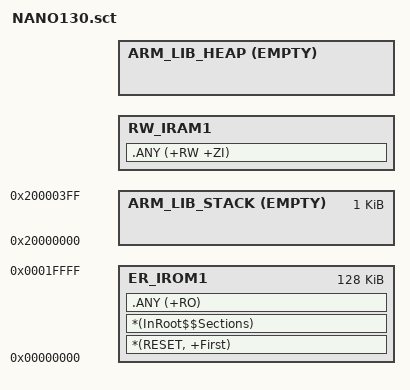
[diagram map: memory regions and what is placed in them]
#! armcc -E

; 512 KB APROM
#if !defined(MBED_APP_START)
  #define MBED_APP_START            0x00000000
#endif

#if !defined(MBED_APP_SIZE)
  #define MBED_APP_SIZE             0x00020000
#endif

; 16 KB SRAM (internal)
#if !defined(MBED_RAM_START)
  #define MBED_RAM_START            0x20000000
#endif

#if !defined(MBED_RAM_SIZE)
  #define MBED_RAM_SIZE             0x4000
#endif


#if !defined(MBED_BOOT_STACK_SIZE)
  #define MBED_BOOT_STACK_SIZE      0x400
#endif

; Does not support vector table relocation

LR_IROM1 MBED_APP_START  MBED_APP_SIZE  {
  ER_IROM1 MBED_APP_START  MBED_APP_SIZE  {  ; load address = execution address
   *(RESET, +First)
   *(InRoot$$Sections)
   .ANY (+RO)
  }

  ARM_LIB_STACK  MBED_RAM_START  EMPTY  MBED_BOOT_STACK_SIZE  {
  }

  RW_IRAM1  AlignExpr(+0, 16)  {  ; 16 byte-aligned
   .ANY (+RW +ZI)
  }
  
  ; Extern SRAM for HEAP
  ARM_LIB_HEAP  AlignExpr(+0, 16)  EMPTY  (MBED_RAM_START + MBED_RAM_SIZE - AlignExpr(ImageLimit(RW_IRAM1), 16))  {
  }
}
ScatterAssert(LoadLimit(LR_IROM1) <= (MBED_APP_START + MBED_APP_SIZE))    ; 128 KB APROM
ScatterAssert(ImageLimit(RW_IRAM1) <= (MBED_RAM_START + MBED_RAM_SIZE))   ; 16 KB SRAM (internal)

